# GD32H77x_78x register map
File version: 1.0
CPU: CM7 r1p2, little endian, MPU, FPU, 4 interrupt priority bits
Registers are 32-bit, read-write, reset 0x0 unless marked. A register's access mark holds for its fields unless they carry their own. Offsets are from the block's base; [hi:lo] are bit positions; {n}, {i} and the like mark numbered series; 'fields as' and 'values as' point back to an identical list.

## SYSCFG — System and memory architectur
Base 0x58000400
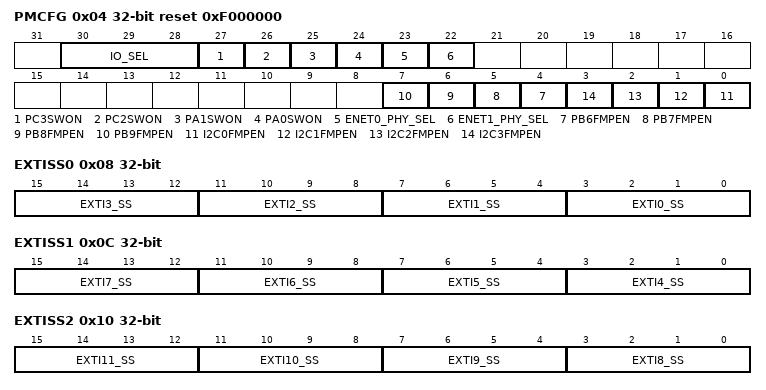
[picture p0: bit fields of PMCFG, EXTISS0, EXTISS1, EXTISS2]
0x04 PMCFG reset 0xF000000 — Peripheral mode configuration register
  [30:28] IO_SEL — Coder IO select
  [27] PC3SWON — PC3 switch open
  [26] PC2SWON — PC2 switch open
  [25] PA1SWON — PA1 switch open
  [24] PA0SWON — PA0 switch open
  [23] ENET0_PHY_SEL — Ethernet0 PHY interface selection
  [22] ENET1_PHY_SEL — Ethernet1 PHY interface selection
  [n-2] PB{n}FMPEN (n=6..9) — I2C Fm+ mode on PB{n} pin enable
  [n] I2C{n}FMPEN (n=0..3) — I2C{n} Fm+ mode enable
0x08 EXTISS0 — EXTI sources selection register 0
  [4n+3:4n] EXTI{n}_SS (n=0..3) — EXTI {n} sources selection
0x0C EXTISS1 — EXTI sources selection register 1
  [4n-13:4n-16] EXTI{n}_SS (n=4..7) — EXTI {n} sources selection
0x10 EXTISS2 — EXTI sources selection register 2
  [4n-29:4n-32] EXTI{n}_SS (n=8..11) — EXTI {n} sources selection
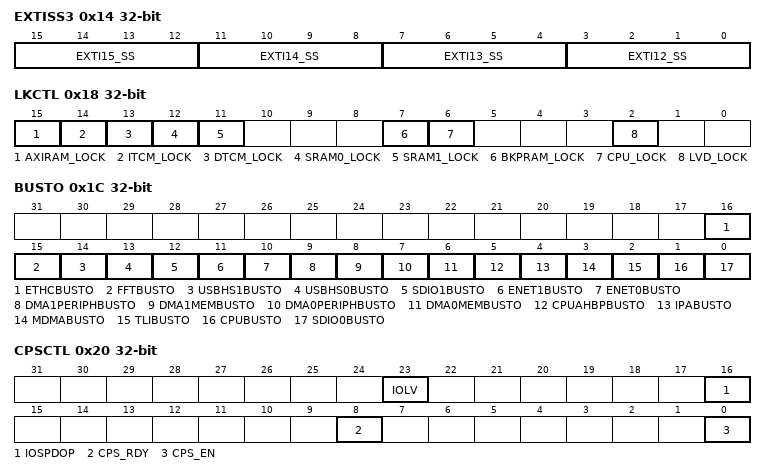
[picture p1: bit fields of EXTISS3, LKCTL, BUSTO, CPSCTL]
0x14 EXTISS3 — EXTI sources selection register 3
  [4n-45:4n-48] EXTI{n}_SS (n=12..15) — EXTI {n} sources selection
0x18 LKCTL — Lockup control register
  [15] AXIRAM_LOCK — Region 0 AXI-SRAM ECC double error lock bit
  [14] ITCM_LOCK — Region 0 ITCM-RAM ECC double error lock bit
  [13] DTCM_LOCK — Region 0 DTCM ECC double error lock bit
  [12] SRAM0_LOCK — Region 1 SRAM0 ECC double error lockup bit
  [11] SRAM1_LOCK — Region 1 SRAM1 ECC double error lockup bit
  [7] BKPRAM_LOCK — Region 2 backup SRAM ECC double error lockup bit
  [6] CPU_LOCK — CPU lockup bit
  [2] LVD_LOCK — Low voltage detector lockup bit
0x1C BUSTO — Bus timeout enable register
  [16] ETHCBUSTO — ETHC bus timeout enable bit.
  [15] FFTBUSTO — FFT bus timeout enable bit.
  [14] USBHS1BUSTO — USBHS1 bus timeout enable bit.
  [13] USBHS0BUSTO — USBHS0 bus timeout enable bit.
  [12] SDIO1BUSTO — SDIO1 bus timeout enable bit.
  [11] ENET1BUSTO — ENET1 bus timeout enable bit.
  [10] ENET0BUSTO — ENET0 bus timeout enable bit.
  [9] DMA1PERIPHBUSTO — DMA1_PERIPH bus timeout enable bit.
  [8] DMA1MEMBUSTO — DMA1_MEM bus timeout enable bit.
  [7] DMA0PERIPHBUSTO — DMA0_PERIPH bus timeout enable bit.
  [6] DMA0MEMBUSTO — DMA0_MEM bus timeout enable bit.
  [5] CPUAHBPBUSTO — CPU-AHBP bus timeout enable bit.
  [4] IPABUSTO — IPA bus timeout enable bit.
  [3] MDMABUSTO — MDMA bus timeout enable bit.
  [2] TLIBUSTO — TLI bus timeout enable bit.
  [1] CPUBUSTO — CPU bus timeout enable bit.
  [0] SDIO0BUSTO — SDIO0 bus timeout enable bit.
0x20 CPSCTL access per field — I/O compensation control register
  [23] IOLV ro — I/O in low voltage state
  [16] IOSPDOP rw — I/O speed optimization, High-speed at low-voltage
  [8] CPS_RDY ro — Compensation cell ready flag
  [0] CPS_EN rw — I/O compensation cell enable
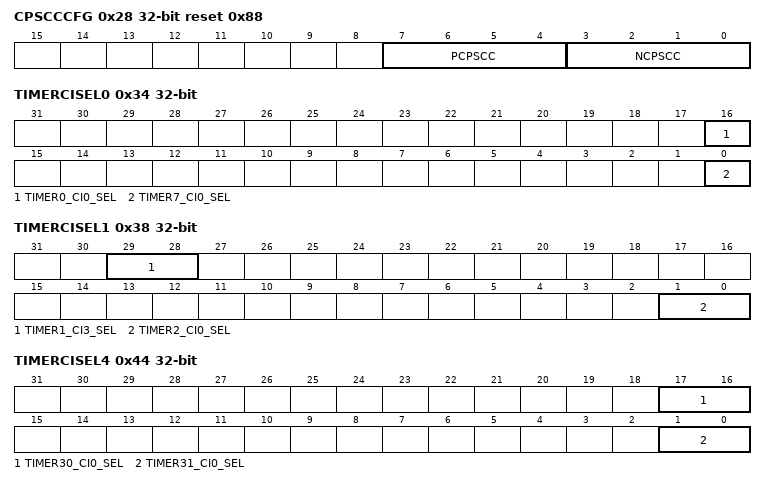
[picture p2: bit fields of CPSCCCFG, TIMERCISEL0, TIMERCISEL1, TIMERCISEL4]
0x28 CPSCCCFG reset 0x88 — I/O compensation cell code configuration register
  [7:4] PCPSCC — PMOS compensation cell code
  [3:0] NCPSCC — NMOS compensation cell code
0x34 TIMERCISEL0 — Timer input selection register 0
  [16] TIMER0_CI0_SEL — Selects TIMER0_CI0 input selection
  [0] TIMER7_CI0_SEL — Selects TIMER7_CI0 input selection
0x38 TIMERCISEL1 — Timer input selection register 1
  [29:28] TIMER1_CI3_SEL — TIMER1_CI3 input selection
  [1:0] TIMER2_CI0_SEL — TIMER2_CI0 input selection
0x40 TIMERCISEL3 — Timer input selection register 3
  [29:28] TIMER22_CI3_SEL — TIMER22_CI3 input selection
0x44 TIMERCISEL4 — Timer input selection register 4
  [17:16] TIMER30_CI0_SEL — TIMER30_CI0 input selection
  [1:0] TIMER31_CI0_SEL — TIMER31_CI0 input selection
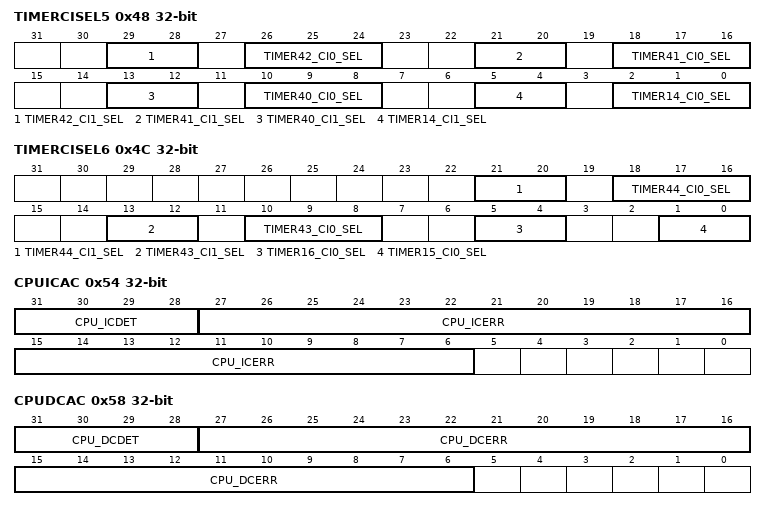
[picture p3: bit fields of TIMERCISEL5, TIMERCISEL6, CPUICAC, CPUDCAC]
0x48 TIMERCISEL5 — Timer input selection register 5
  [29:28] TIMER42_CI1_SEL — Selects TIMER42_CI1 input
  [26:24] TIMER42_CI0_SEL — Selects TIMER42_CI0 input
  [21:20] TIMER41_CI1_SEL — Selects TIMER41_CI1 input
  [18:16] TIMER41_CI0_SEL — Selects TIMER41_CI0 input
  [13:12] TIMER40_CI1_SEL — Selects TIMER40_CI1 input
  [10:8] TIMER40_CI0_SEL — Selects TIMER40_CI0 input
  [5:4] TIMER14_CI1_SEL — Selects TIMER14_CI1 input
  [2:0] TIMER14_CI0_SEL — Selects TIMER14_CI0 input
0x4C TIMERCISEL6 — Timer input selection register 6
  [21:20] TIMER44_CI1_SEL — Selects TIMER44_CI1 input
  [18:16] TIMER44_CI0_SEL — Selects TIMER44_CI0 input
  [13:12] TIMER43_CI1_SEL — Selects TIMER43_CI1 input
  [10:8] TIMER43_CI0_SEL — Selects TIMER43_CI0 input
  [5:4] TIMER16_CI0_SEL — Selects TIMER16_CI0 input
  [1:0] TIMER15_CI0_SEL — Selects TIMER15_CI0 input
0x54 CPUICAC access per field — CPU ICACHE error status registe
  [31:28] CPU_ICDET rw — The ICACHE error detection information
  [27:6] CPU_ICERR ro — The ICACHE error bank information
0x58 CPUDCAC access per field — CPU DCACHE error status register
  [31:28] CPU_DCDET rw — The DCACHE error detection information
  [27:6] CPU_DCERR ro — The DCACHE error bank information
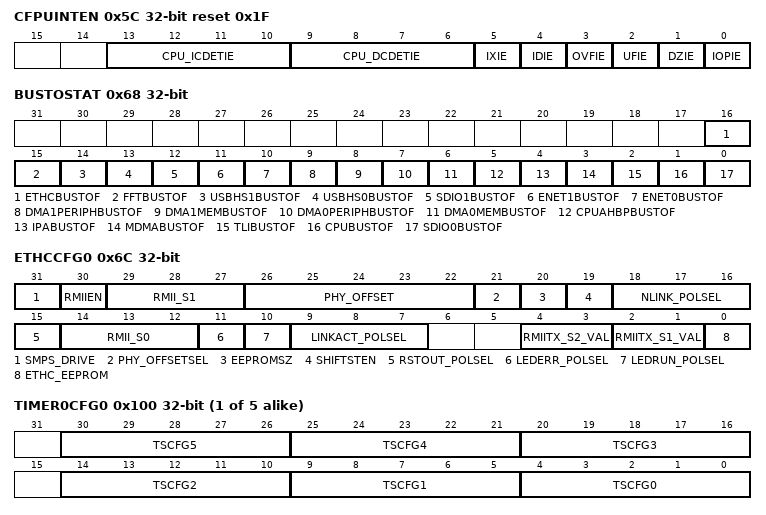
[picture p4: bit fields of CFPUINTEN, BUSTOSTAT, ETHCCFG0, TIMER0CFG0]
0x5C CFPUINTEN reset 0x1F — CACHE and FPU interrupt enable register
  [13:10] CPU_ICDETIE — icache error detection information int enable
  [9:6] CPU_DCDETIE — dcache error bank information int enable
  [5] IXIE — Inexact interrupt enable bit
  [4] IDIE — Input denormal interrupt enable bit
  [3] OVFIE — Overflow interrupt enable bit
  [2] UFIE — Underflow interrupt enable bit
  [1] DZIE — Divide by 0 interrupt enable bit
  [0] IOPIE — Invalid operation interrupt enable bit
0x64 SRAMCFG0 — SRAM configuration register 0
  [1:0] SECURE_SRAM_SIZE — Size of secure SRAM
0x68 BUSTOSTAT — Bus timeout states register
  [16] ETHCBUSTOF — ETHC bus timeout flag bit.
  [15] FFTBUSTOF — FFT bus timeout flag bit.
  [14] USBHS1BUSTOF — USBHS1 bus timeout flag bit.
  [13] USBHS0BUSTOF — USBHS0 bus timeout flag bit.
  [12] SDIO1BUSTOF — SDIO1 bus timeout flag bit.
  [11] ENET1BUSTOF — ENET1 bus timeout flag bit.
  [10] ENET0BUSTOF — ENET0 bus timeout enable flag bit.
  [9] DMA1PERIPHBUSTOF — DMA1_PERIPH bus timeout flag bit.
  [8] DMA1MEMBUSTOF — DMA1_MEM bus timeout flag bit.
  [7] DMA0PERIPHBUSTOF — DMA0_PERIPH bus timeout flag bit.
  [6] DMA0MEMBUSTOF — DMA0_MEM bus timeout flag bit.
  [5] CPUAHBPBUSTOF — CPU-AHBP bus timeout flag bit.
  [4] IPABUSTOF — IPA bus timeout flag bit.
  [3] MDMABUSTOF — MDMA bus timeout flag bit.
  [2] TLIBUSTOF — TLI bus timeout flag bit.
  [1] CPUBUSTOF — CPU bus timeout flag bit.
  [0] SDIO0BUSTOF — SDIO0 bus timeout flag bit.
0x6C ETHCCFG0 — ETHC configuration register 0
  [31] SMPS_DRIVE — SMPS_DRIVE's drive capability
  [30] RMIIEN — RMII port enable bit.
  [29:27] RMII_S1 — Clock compensation phase setting in RMII mode.
  [26:22] PHY_OFFSET — PHY address offset.
  [21] PHY_OFFSETSEL — Whether to enable the PHY address offset function of ETHC.
  [20] EEPROMSZ — Internal EEPROM capacity of ETHC.
  [19] SHIFTSTEN — Whether to enable the latch function of tx_shift.
  [18:16] NLINK_POLSEL — NLINK signal input level polarity selection bits
  [15] RSTOUT_POLSEL — Reset_out signal output active polarity selection
  [14:12] RMII_S0 — Clock compensation phase setting in RMII mode.
  [11] LEDERR_POLSEL — led_err signal output active polarity selection
  [10] LEDRUN_POLSEL — led_run signal output active polarity selection
  [9:7] LINKACT_POLSEL — link_act signal output active polarity selection
  [4:3] RMIITX_S2_VAL — tx_shift value of RMII SHIFT2
  [2:1] RMIITX_S1_VAL — tx_shift value of RMII SHIFT1
  [0] ETHC_EEPROM — ETHC EEPROM configuration
0x70 ETHCCFG1 — ETHC configuration register 1
  [31:0] ETHC_SRAM — ETHC SRAM configuration bits
0x74 ETHCCFG2 — ETHC configuration register 2
  [31:0] RST_OUT_CNT — The number of clock cycles for which reset_out is held. Clock cycle is 10ns.
{0x100+0xC*i} TIMER{i}CFG0 (i=0..4) — TIMER{i} configuration register 0
  [30:26] TSCFG5 — Event mode configuration
  [25:21] TSCFG4 — Pause mode configuration
  [20:16] TSCFG3 — Restart mode configuration
  [14:10] TSCFG2 — Quadrature decoder mode 2 configuration
  [9:5] TSCFG1 — Quadrature decoder mode 1 configuration
  [4:0] TSCFG0 — Quadrature decoder mode 0 configuration
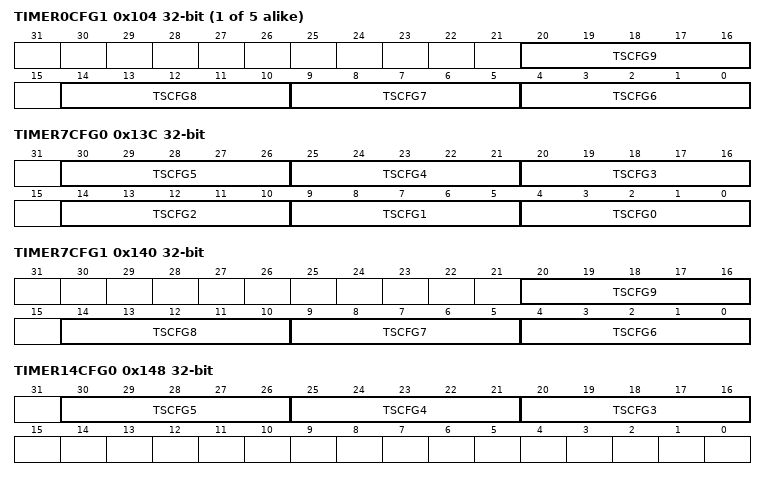
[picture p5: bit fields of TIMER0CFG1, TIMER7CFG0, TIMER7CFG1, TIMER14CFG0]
{0x104+0xC*i} TIMER{i}CFG1 (i=0..4) — TIMER{i} configuration register 1
  [20:16] TSCFG9 — Non-quadrature decoder mode 1 configuration
  [14:10] TSCFG8 — Non-quadrature decoder mode 0 configuration
  [9:5] TSCFG7 — Restart or event mode configuration
  [4:0] TSCFG6 — External clock mode 0 configuration
{0x108+0xC*i} TIMER{i}CFG2 (i=0..4) — TIMER{i} configuration register 2
  [20:16] TSCFG15 — Internal trigger input source configuration
0x13C TIMER7CFG0 — TIMER7 configuration register 0
  fields as TIMER0CFG0
0x140 TIMER7CFG1 — TIMER7 configuration register 1
  fields as TIMER0CFG1
0x144 TIMER7CFG2 — TIMER7 configuration register 2
  [20:16] TSCFG15 — Internal trigger input source configuration
0x148 TIMER14CFG0 — TIMER14 configuration register 0
  [30:26] TSCFG5 — Event mode configuration
  [25:21] TSCFG4 — Pause mode configuration
  [20:16] TSCFG3 — Restart mode configuration
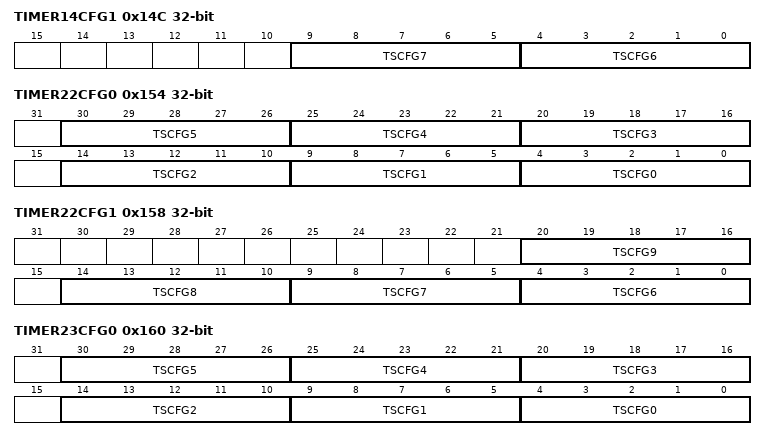
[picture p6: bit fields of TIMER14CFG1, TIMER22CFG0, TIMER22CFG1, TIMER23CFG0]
0x14C TIMER14CFG1 — TIMER14 configuration register 1
  [9:5] TSCFG7 — Restart or event mode configuration
  [4:0] TSCFG6 — External clock mode 0 configuration
0x150 TIMER14CFG2 — TIMER14 configuration register 2
  [20:16] TSCFG15 — Internal trigger input source configuration
0x154 TIMER22CFG0 — TIMER22 configuration register 0
  fields as TIMER0CFG0
0x158 TIMER22CFG1 — TIMER22 configuration register 1
  fields as TIMER0CFG1
0x15C TIMER22CFG2 — TIMER22 configuration register 2
  [20:16] TSCFG15 — Internal trigger input source configuration
0x160 TIMER23CFG0 — TIMER23 configuration register 0
  fields as TIMER0CFG0
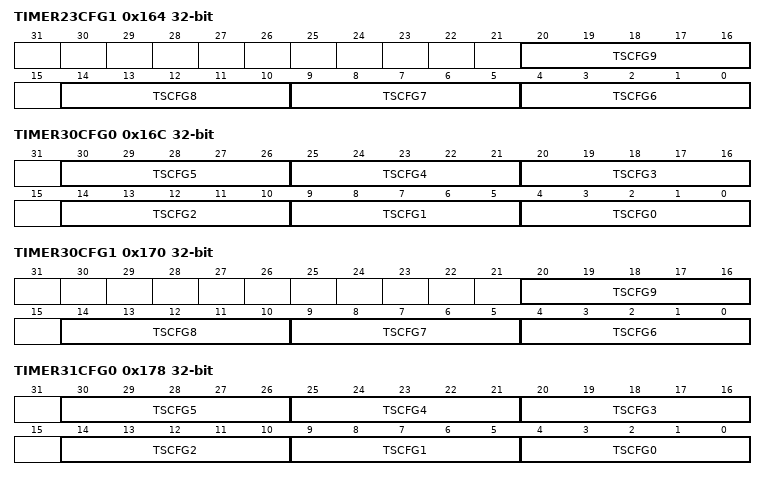
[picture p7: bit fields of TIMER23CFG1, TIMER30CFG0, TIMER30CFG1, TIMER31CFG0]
0x164 TIMER23CFG1 — TIMER23 configuration register 1
  fields as TIMER0CFG1
0x168 TIMER23CFG2 — TIMER23 configuration register 2
  [20:16] TSCFG15 — Internal trigger input source configuration
0x16C TIMER30CFG0 — TIMER30 configuration register 0
  fields as TIMER0CFG0
0x170 TIMER30CFG1 — TIMER30 configuration register 1
  fields as TIMER0CFG1
0x174 TIMER30CFG2 — TIMER30 configuration register 2
  [20:16] TSCFG15 — Internal trigger input source configuration
0x178 TIMER31CFG0 — TIMER31 configuration register 0
  fields as TIMER0CFG0
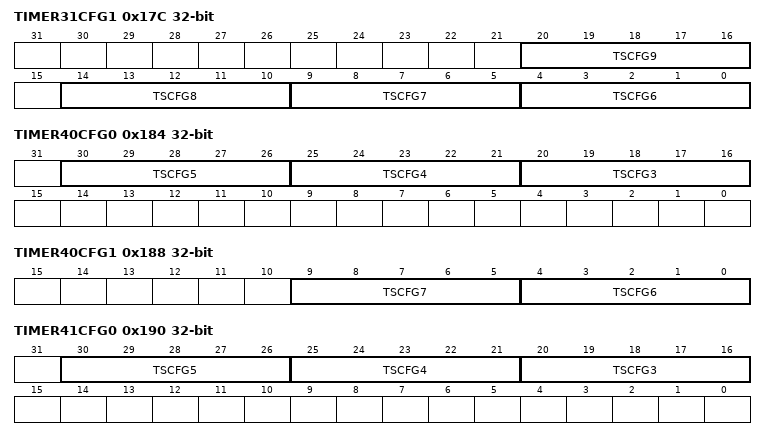
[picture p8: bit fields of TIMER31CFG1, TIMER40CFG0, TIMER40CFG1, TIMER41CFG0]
0x17C TIMER31CFG1 — TIMER31 configuration register 1
  fields as TIMER0CFG1
0x180 TIMER31CFG2 — TIMER31 configuration register 2
  [20:16] TSCFG15 — Internal trigger input source configuration
0x184 TIMER40CFG0 — TIMER40 configuration register 0
  fields as TIMER14CFG0
0x188 TIMER40CFG1 — TIMER40 configuration register 1
  fields as TIMER14CFG1
0x18C TIMER40CFG2 — TIMER40 configuration register 2
  [20:16] TSCFG15 — Internal trigger input source configuration
0x190 TIMER41CFG0 — TIMER41 configuration register 0
  fields as TIMER14CFG0
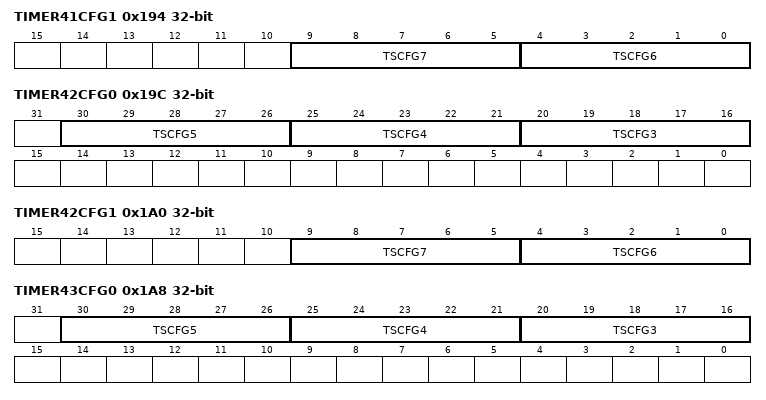
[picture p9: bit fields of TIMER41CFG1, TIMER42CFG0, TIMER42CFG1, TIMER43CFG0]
0x194 TIMER41CFG1 — TIMER41 configuration register 1
  fields as TIMER14CFG1
0x198 TIMER41CFG2 — TIMER41 configuration register 2
  [20:16] TSCFG15 — Internal trigger input source configuration
0x19C TIMER42CFG0 — TIMER42 configuration register 0
  fields as TIMER14CFG0
0x1A0 TIMER42CFG1 — TIMER42 configuration register 1
  fields as TIMER14CFG1
0x1A4 TIMER42CFG2 — TIMER42 configuration register 2
  [20:16] TSCFG15 — Internal trigger input source configuration
0x1A8 TIMER43CFG0 — TIMER43 configuration register 0
  fields as TIMER14CFG0
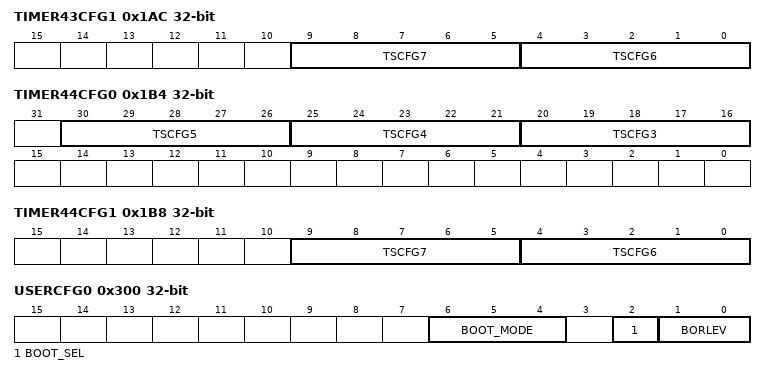
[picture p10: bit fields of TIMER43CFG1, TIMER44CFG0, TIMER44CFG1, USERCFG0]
0x1AC TIMER43CFG1 — TIMER43 configuration register 1
  fields as TIMER14CFG1
0x1B0 TIMER43CFG2 — TIMER43 configuration register 2
  [20:16] TSCFG15 — Internal trigger input source configuration
0x1B4 TIMER44CFG0 — TIMER44 configuration register 0
  fields as TIMER14CFG0
0x1B8 TIMER44CFG1 — TIMER44 configuration register 1
  fields as TIMER14CFG1
0x1BC TIMER44CFG2 — TIMER44 configuration register 2
  [20:16] TSCFG15 — Internal trigger input source configuration
0x300 USERCFG0 ro — User configuration register 0
  [6:4] BOOT_MODE
  [2] BOOT_SEL — Boot select
  [1:0] BORLEV — BOR Brownout reset threshold level
